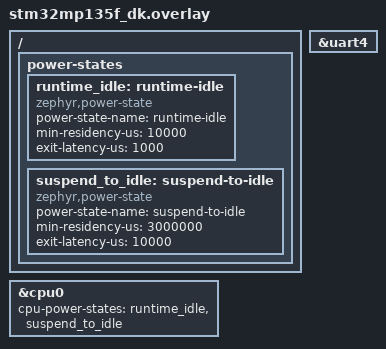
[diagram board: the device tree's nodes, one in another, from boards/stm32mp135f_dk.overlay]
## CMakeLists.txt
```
cmake_minimum_required(VERSION 3.20.0)
find_package(Zephyr REQUIRED HINTS $ENV{ZEPHYR_BASE})
project(lowpowerentry)

set(CUBE_ROOT /local/home/achraftm/zephyrproject/mp13BareMetal/stm32cubemp13-v1-2-0/STM32Cube_FW_MP13_V1.2.0)
set(CUBE_BSP_DIR ${CUBE_ROOT}/Drivers/BSP/STM32MP13xx_DISCO)
set(CUBE_HAL_DIR ${CUBE_ROOT}/Drivers/STM32MP13xx_HAL_Driver/Inc)
set(CUBE_CMSIS_DIR ${CUBE_ROOT}/Drivers/CMSIS/Device/ST/STM32MP13xx/Include)
set(CUBE_BSP_APP_INC ${CUBE_ROOT}/Projects/STM32MP135C-DK/Applications/Low_power_LPLV_Stop2/BSP_BasicTemplates_low_power/Inc)

zephyr_include_directories(
	${CMAKE_CURRENT_SOURCE_DIR}
	${CUBE_BSP_DIR}
)

target_sources(app PRIVATE
	src/main.c
	src/wakeWrap.c
	${ZEPHYR_BASE}/../modules/hal/stm32/stm32cube/stm32mp13xx/drivers/src/stm32mp13xx_hal_pwr.c
	${ZEPHYR_BASE}/../modules/hal/stm32/stm32cube/stm32mp13xx/drivers/src/stm32mp13xx_hal_pwr_ex.c
	${ZEPHYR_BASE}/../modules/hal/stm32/stm32cube/stm32mp13xx/drivers/src/stm32mp13xx_hal_gpio.c
	${ZEPHYR_BASE}/../modules/hal/stm32/stm32cube/stm32mp13xx/drivers/src/stm32mp13xx_hal_exti.c
	${ZEPHYR_BASE}/../modules/hal/stm32/stm32cube/stm32mp13xx/drivers/src/stm32mp13xx_hal_i2c.c
	${ZEPHYR_BASE}/../modules/hal/stm32/stm32cube/stm32mp13xx/drivers/src/stm32mp13xx_hal_uart.c
	${ZEPHYR_BASE}/../modules/hal/stm32/stm32cube/stm32mp13xx/drivers/src/stm32mp13xx_hal_rtc.c
	${ZEPHYR_BASE}/../modules/hal/stm32/stm32cube/stm32mp13xx/drivers/src/stm32mp13xx_hal_rtc_ex.c
	${ZEPHYR_BASE}/../modules/hal/stm32/stm32cube/stm32mp13xx/drivers/src/stm32mp13xx_hal_ddr.c
	${ZEPHYR_BASE}/../modules/hal/stm32/stm32cube/stm32mp13xx/drivers/src/stm32mp13xx_hal_bsec.c
	${CUBE_ROOT}/Drivers/CMSIS/Core_A/Source/irq_ctrl_gic.c
	${CUBE_BSP_DIR}/stm32mp13xx_disco.c
	${CUBE_BSP_DIR}/stm32mp13xx_disco_bus.c
	${CUBE_BSP_DIR}/stm32mp13xx_disco_stpmic1.c
)

target_include_directories(app PRIVATE
	${CUBE_BSP_APP_INC}
	${CUBE_ROOT}/Drivers/CMSIS/Core_A/Include
	${CUBE_HAL_DIR}
	${CUBE_CMSIS_DIR}
)

target_compile_definitions(app PRIVATE
	USE_STM32MP13XX_DK
	HAL_DDR_MODULE_ENABLED
	DDR_TYPE_DDR3_4Gb
	HAL_BSEC_MODULE_ENABLED
)
```

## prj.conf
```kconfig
CONFIG_PRINTK=y
CONFIG_CONSOLE=y
CONFIG_SERIAL=y
CONFIG_UART_CONSOLE=y
CONFIG_STDOUT_CONSOLE=y
CONFIG_PM=y
CONFIG_TICKLESS_KERNEL=y
```

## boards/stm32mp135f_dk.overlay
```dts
&uart4 {
	/delete-property/ wakeup-source;
};

/ {
	power-states {
		runtime_idle: runtime-idle {
			compatible = "zephyr,power-state";
			power-state-name = "runtime-idle";
			min-residency-us = <10000>;
			exit-latency-us = <1000>;
		};

		suspend_to_idle: suspend-to-idle {
			compatible = "zephyr,power-state";
			power-state-name = "suspend-to-idle";
			min-residency-us = <3000000>;
			exit-latency-us = <10000>;
		};
	};
};

&cpu0 {
	cpu-power-states = <&runtime_idle &suspend_to_idle>;
};
```

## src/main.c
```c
#include "main.h"
#include <zephyr/sys/printk.h>
#include <zephyr/pm/pm.h>
#include <zephyr/pm/state.h>
#include <zephyr/devicetree.h>
#include <zephyr/drivers/gpio.h>
#include "src/wakeWrap.h"

RTC_HandleTypeDef RTCHandle_BKUP;


int main(void)
{
	printk("Hello World - Landed in user application in DDR\n\r");
	uint32_t count = 0;

	HAL_RTC_Init(&RTCHandle_BKUP);
	printk("step: backup register written\n\r");
	//HAL_RTCEx_BKUPWrite(&RTCHandle_BKUP, RTC_BKP_DR0,(uint32_t) (&main));

	while (count < 6) {
		BSP_LED_Toggle(LED_BLUE);
		k_busy_wait(100000); /* 100 ms */
		BSP_LED_Toggle(LED_RED);
		count++;
	}

	BSP_LED_Off(LED_BLUE);
	BSP_LED_Off(LED_RED);

	HAL_PWR_EnableWakeUpPinIT(PWR_WAKEUP_PIN1);
	HAL_PWR_EnableWakeUpPin(PWR_WAKEUP_PIN1_LOW);
	IRQ_Enable(MPU_WAKEUP_PIN_IRQn);
	HAL_Delay(1000);

	while (1) {
		BSP_LED_Toggle(LED_BLUE);
		k_busy_wait(100000); /* 100 ms */
		BSP_LED_Toggle(LED_RED);
	}
}
```

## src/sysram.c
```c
#include <stdint.h>
#include <string.h>

#include <stm32mp13xx_hal.h>
#include <stm32mp13xx_hal_rtc.h>
#include <stm32mp13xx_hal_rtc_ex.h>

#include "sysram.h"

#define SYSRAM_START 0x2FFE0000U
#define SYSRAM_END   0x30000000U

#define DDRCTRL_BASE_ADDR  0x5A003000U
#define DDRPHYC_BASE_ADDR  0x5A004000U
#define PWR_BASE_ADDR      0x50001000U
#define TAMP_BASE_ADDR     0x5C00A000U

#define DDRCTRL_STAT_OFFSET    0x004U
#define DDRCTRL_PWRCTL_OFFSET  0x030U
#define DDRPHYC_ZQ0CR0_OFFSET  0x180U
#define PWR_CR3_OFFSET         0x00CU
#define TAMP_BKP2R_OFFSET      0x108U

#define DDRCTRL_STAT_OPERATING_MODE_NML  0x00000001U
#define DDRCTRL_STAT_OPERATING_MODE_SR   0x00000003U
#define DDRCTRL_STAT_SELFREF_TYPE_SW     0x00000020U

#ifndef DDRCTRL_STAT_OPERATING_MODE_Msk
#define DDRCTRL_STAT_OPERATING_MODE_Msk  0x00000007U
#endif

#ifndef DDRCTRL_STAT_SELFREF_TYPE_Msk
#define DDRCTRL_STAT_SELFREF_TYPE_Msk    0x00000030U
#endif

#ifndef DDRCTRL_PWRCTL_SELFREF_SW
#define DDRCTRL_PWRCTL_SELFREF_SW        0x00000020U
#endif

#ifndef DDRCTRL_PWRCTL_SELFREF_EN
#define DDRCTRL_PWRCTL_SELFREF_EN        0x00000001U
#endif

#ifndef DDRCTRL_PWRCTL_EN_DFI_DRAM_CLK_DISABLE
#define DDRCTRL_PWRCTL_EN_DFI_DRAM_CLK_DISABLE 0x00000008U
#endif

#ifndef DDRPHYC_ZQ0CR0_ZDATA_Msk
#define DDRPHYC_ZQ0CR0_ZDATA_Msk         0x000FFFFFU
#endif

#ifndef PWR_CR3_DDRSREN
#define PWR_CR3_DDRSREN                  0x00010000U
#endif

#ifndef PWR_CR3_DDRRETEN
#define PWR_CR3_DDRRETEN                 0x00020000U
#endif

/* GPIO A LED control (LD3 is active-low on pin 14). */
#define GPIOA_BASE_ADDR   0x50002000U
#define GPIO_MODER_OFFSET 0x00U
#define GPIO_OTYPER_OFFSET 0x04U
#define GPIO_PUPDR_OFFSET 0x0CU
#define GPIO_BSRR_OFFSET  0x18U
#define LED_PIN           14U
#define LED_PIN_MASK      (1U << LED_PIN)

#define STUB_WAIT_TIMEOUT      50000000U
#define BLINK_HALF_PERIOD_NOPS 200000U

#define SYSRAM_DDR_SW_SELF_REFRESH_MODE 0x0U
#define SYSRAM_DDR_AUTO_SELF_REFRESH_MODE 0x1U
#define SYSRAM_DDR_HW_SELF_REFRESH_MODE 0x2U
#define SYSRAM_DDR_INVALID_MODE 0x3U

extern uint8_t __sysram_text_start[];
extern uint8_t __sysram_text_end[];
extern uint8_t __sysram_text_load_start[];

__attribute__((section(".sysram_bss")))
static struct ddr_sr_result sysram_result;

__attribute__((section(".sysram_bss"), aligned(8)))
static uint8_t sysram_stack[1024];

static inline uint32_t mmio_read32(uint32_t addr)
{
	return *(volatile uint32_t *)addr;
}

static inline void mmio_write32(uint32_t addr, uint32_t val)
{
	*(volatile uint32_t *)addr = val;
}

static inline void mmio_set_bits32(uint32_t addr, uint32_t mask)
{
	mmio_write32(addr, mmio_read32(addr) | mask);
}

static inline void mmio_clear_bits32(uint32_t addr, uint32_t mask)
{
	mmio_write32(addr, mmio_read32(addr) & ~mask);
}

extern RTC_HandleTypeDef RTCHandle_BKUP;

static HAL_StatusTypeDef ddr_sr_mode_ssr(void)
{
	const uint32_t pwrctl_addr = DDRCTRL_BASE_ADDR + DDRCTRL_PWRCTL_OFFSET;

	/* SW mode in HAL: no auto self-refresh and no clock-disable LP mode. */
	mmio_clear_bits32(pwrctl_addr,
			      DDRCTRL_PWRCTL_EN_DFI_DRAM_CLK_DISABLE |
			      DDRCTRL_PWRCTL_SELFREF_EN);

	return HAL_OK;
}

static HAL_StatusTypeDef ddr_sr_mode_asr(void)
{
	const uint32_t pwrctl_addr = DDRCTRL_BASE_ADDR + DDRCTRL_PWRCTL_OFFSET;

	/* ASR mode in HAL: auto self-refresh + clock-disable LP mode. */
	mmio_set_bits32(pwrctl_addr,
		    DDRCTRL_PWRCTL_EN_DFI_DRAM_CLK_DISABLE |
		    DDRCTRL_PWRCTL_SELFREF_EN);

	return HAL_OK;
}

static HAL_StatusTypeDef ddr_sr_mode_hsr(void)
{
	const uint32_t pwrctl_addr = DDRCTRL_BASE_ADDR + DDRCTRL_PWRCTL_OFFSET;

	/* HSR mode in HAL: clock-disable LP mode enabled, auto self-refresh disabled. */
	mmio_set_bits32(pwrctl_addr, DDRCTRL_PWRCTL_EN_DFI_DRAM_CLK_DISABLE);
	mmio_clear_bits32(pwrctl_addr, DDRCTRL_PWRCTL_SELFREF_EN);

	return HAL_OK;
}

static uint32_t ddr_sr_read_mode(void)
{
	const uint32_t pwrctl_addr = DDRCTRL_BASE_ADDR + DDRCTRL_PWRCTL_OFFSET;
	uint32_t pwrctl = mmio_read32(pwrctl_addr);

	switch (pwrctl & (DDRCTRL_PWRCTL_EN_DFI_DRAM_CLK_DISABLE |
				 DDRCTRL_PWRCTL_SELFREF_EN)) {
	case 0U:
		return SYSRAM_DDR_SW_SELF_REFRESH_MODE;
	case DDRCTRL_PWRCTL_EN_DFI_DRAM_CLK_DISABLE:
		return SYSRAM_DDR_HW_SELF_REFRESH_MODE;
	case DDRCTRL_PWRCTL_EN_DFI_DRAM_CLK_DISABLE | DDRCTRL_PWRCTL_SELFREF_EN:
		return SYSRAM_DDR_AUTO_SELF_REFRESH_MODE;
	default:
		return SYSRAM_DDR_INVALID_MODE;
	}
}

/* HAL-like helper: enter software self-refresh and wait for status transition. */
static HAL_StatusTypeDef ddr_sw_self_refresh_in(void)
{
	uint32_t stat;
	uint32_t timeout;
	const uint32_t pwrctl_addr = DDRCTRL_BASE_ADDR + DDRCTRL_PWRCTL_OFFSET;
	const uint32_t stat_addr = DDRCTRL_BASE_ADDR + DDRCTRL_STAT_OFFSET;

	mmio_set_bits32(pwrctl_addr, DDRCTRL_PWRCTL_SELFREF_SW);

	timeout = STUB_WAIT_TIMEOUT;
	do {
		stat = mmio_read32(stat_addr);
		if (((stat & DDRCTRL_STAT_OPERATING_MODE_Msk) == DDRCTRL_STAT_OPERATING_MODE_SR) &&
		    ((stat & DDRCTRL_STAT_SELFREF_TYPE_Msk) == DDRCTRL_STAT_SELFREF_TYPE_SW)) {
			return HAL_OK;
		}
	} while (--timeout != 0U);

	return HAL_TIMEOUT;
}

/* HAL-like helper: clear software self-refresh request and wait for normal mode. */
static HAL_StatusTypeDef ddr_sw_self_refresh_out(void)
{
	uint32_t stat;
	uint32_t timeout;
	const uint32_t pwrctl_addr = DDRCTRL_BASE_ADDR + DDRCTRL_PWRCTL_OFFSET;
	const uint32_t stat_addr = DDRCTRL_BASE_ADDR + DDRCTRL_STAT_OFFSET;

	mmio_clear_bits32(pwrctl_addr, DDRCTRL_PWRCTL_SELFREF_SW);

	timeout = STUB_WAIT_TIMEOUT;
	do {
		stat = mmio_read32(stat_addr);
		if ((stat & DDRCTRL_STAT_OPERATING_MODE_Msk) == DDRCTRL_STAT_OPERATING_MODE_NML) {
			return HAL_OK;
		}
	} while (--timeout != 0U);

	return HAL_TIMEOUT;
}

/* Copied/adapted from HAL_DDR_SR_Entry. */
static HAL_StatusTypeDef sysram_ddr_sr_entry(uint32_t *zq0cr0_zdata)
{
	if (zq0cr0_zdata != NULL) {
		*zq0cr0_zdata = mmio_read32(DDRPHYC_BASE_ADDR + DDRPHYC_ZQ0CR0_OFFSET) & DDRPHYC_ZQ0CR0_ZDATA_Msk;
	}

	if (ddr_sw_self_refresh_in() != HAL_OK) {
		return HAL_ERROR;
	}

	mmio_set_bits32(PWR_BASE_ADDR + PWR_CR3_OFFSET, PWR_CR3_DDRSREN);

	return HAL_OK;
}

/* Copied/adapted from HAL_DDR_SR_Exit. */
static HAL_StatusTypeDef sysram_ddr_sr_exit(void)
{
	HAL_StatusTypeDef ret;

	ret = ddr_sw_self_refresh_out();
	if (ret != HAL_OK) {
		return ret;
	}

	mmio_clear_bits32(PWR_BASE_ADDR + PWR_CR3_OFFSET, PWR_CR3_DDRRETEN);

	return HAL_OK;
}

/* Copied/adapted from HAL_DDR_SR_SetMode. */
static HAL_StatusTypeDef sysram_ddr_sr_setmode(uint32_t mode)
{
	HAL_StatusTypeDef ret;

	switch (mode) {
	case SYSRAM_DDR_SW_SELF_REFRESH_MODE:
		ret = ddr_sr_mode_ssr();
		break;
	case SYSRAM_DDR_AUTO_SELF_REFRESH_MODE:
		ret = ddr_sr_mode_asr();
		break;
	case SYSRAM_DDR_HW_SELF_REFRESH_MODE:
		ret = ddr_sr_mode_hsr();
		break;
	default:
		ret = HAL_ERROR;
		break;
	}

	return ret;
}

/* Copied/adapted from HAL_DDR_SR_ReadMode. */
static uint32_t sysram_ddr_sr_readmode(void)
{
	return ddr_sr_read_mode();
}

/* RTC handoff helper: fetch FSBL entry from BKP_DR2 and jump to it. */
__attribute__((noreturn))
static void sysram_jump_to_fsbl_from_bkp_dr2(void)
{
	uintptr_t jump_target;
	const uint32_t bkp2r_addr = TAMP_BASE_ADDR + TAMP_BKP2R_OFFSET;

	/* Direct read avoids HAL RTC call dependencies during SYSRAM handoff. */
	jump_target = (uintptr_t)mmio_read32(bkp2r_addr);
	__asm__ volatile("bx %0" : : "r"(jump_target) : "memory");
	__builtin_unreachable();
}

static void led_init(void)
{
	uint32_t moder;
	uint32_t otyper;
	uint32_t pupdr;

	moder = mmio_read32(GPIOA_BASE_ADDR + GPIO_MODER_OFFSET);
	moder &= ~(0x3U << (LED_PIN * 2U));
	moder |= (0x1U << (LED_PIN * 2U));
	mmio_write32(GPIOA_BASE_ADDR + GPIO_MODER_OFFSET, moder);

	otyper = mmio_read32(GPIOA_BASE_ADDR + GPIO_OTYPER_OFFSET);
	otyper &= ~LED_PIN_MASK;
	mmio_write32(GPIOA_BASE_ADDR + GPIO_OTYPER_OFFSET, otyper);

	pupdr = mmio_read32(GPIOA_BASE_ADDR + GPIO_PUPDR_OFFSET);
	pupdr &= ~(0x3U << (LED_PIN * 2U));
	mmio_write32(GPIOA_BASE_ADDR + GPIO_PUPDR_OFFSET, pupdr);

	/* Active-low LED off. */
	mmio_write32(GPIOA_BASE_ADDR + GPIO_BSRR_OFFSET, LED_PIN_MASK);
}

static void copy_sysram_sections(void)
{
	size_t size;

	size = (size_t)(__sysram_text_end - __sysram_text_start);
	memcpy(__sysram_text_start, __sysram_text_load_start, size);
}

__attribute__((section(".sysram_text"), noinline, used))
static void ddr_sr_stub(struct ddr_sr_result *result)
{
	uint32_t stat;
	HAL_StatusTypeDef ret;
	const uint32_t stat_addr = DDRCTRL_BASE_ADDR + DDRCTRL_STAT_OFFSET;
	const uint32_t gpioa_bsrr_addr = GPIOA_BASE_ADDR + GPIO_BSRR_OFFSET;

	result->started = 1U;
	result->phase = 1U;

	if (sysram_ddr_sr_setmode(SYSRAM_DDR_SW_SELF_REFRESH_MODE) != HAL_OK) {
		result->phase = 0xE0U;
		return;
	}

	if (sysram_ddr_sr_readmode() != SYSRAM_DDR_SW_SELF_REFRESH_MODE) {
		result->phase = 0xE4U;
		return;
	}

	ret = sysram_ddr_sr_entry(&result->zdata);
	result->phase = 2U;
	stat = mmio_read32(stat_addr);
	result->entry_stat = stat;
	result->entry_ok = (ret == HAL_OK) ? 1U : 0U;
	if (!result->entry_ok) {
		result->phase = 0xE1U;
		return;
	}

	result->phase = 3U;

	for (uint32_t blink_count = 0U; blink_count < 10U; blink_count++) {
		mmio_write32(gpioa_bsrr_addr, LED_PIN_MASK << 16);
		for (volatile uint32_t delay = 0U; delay < BLINK_HALF_PERIOD_NOPS; delay++) {
			__asm__ volatile("nop");
		}

		mmio_write32(gpioa_bsrr_addr, LED_PIN_MASK);
		for (volatile uint32_t delay = 0U; delay < BLINK_HALF_PERIOD_NOPS; delay++) {
			__asm__ volatile("nop");
		}
	}

	sysram_jump_to_fsbl_from_bkp_dr2();

	ret = sysram_ddr_sr_exit();
	result->phase = 4U;
	stat = mmio_read32(stat_addr);
	result->exit_stat = stat;
	result->exit_ok = (ret == HAL_OK) ? 1U : 0U;
	if (!result->exit_ok) {
		result->phase = 0xE2U;
		result->finished = 1U;
		return;
	}

	result->phase = 5U;
	result->finished = 1U;
}

void sysram_init(void)
{
	led_init();
	copy_sysram_sections();
	__asm__ volatile("dsb" ::: "memory");
	__asm__ volatile("isb" ::: "memory");
	memset(&sysram_result, 0, sizeof(sysram_result));
}

__attribute__((section(".sysram_text"), noinline, used))
void sysram_run(void)
{
	register uintptr_t old_sp;
	uintptr_t new_sp = (uintptr_t)(sysram_stack + sizeof(sysram_stack));

	__asm__ volatile("mov %0, sp" : "=r"(old_sp));
	__asm__ volatile("mov sp, %0" : : "r"(new_sp) : "memory");

	ddr_sr_stub(&sysram_result);

	__asm__ volatile("mov sp, %0" : : "r"(old_sp) : "memory");
}

const struct ddr_sr_result *sysram_get_result(void)
{
	return &sysram_result;
}

uintptr_t sysram_get_stub_addr(void)
{
	return (uintptr_t)ddr_sr_stub & ~(uintptr_t)0x1U;
}

uintptr_t sysram_get_result_addr(void)
{
	return (uintptr_t)&sysram_result;
}

uintptr_t sysram_get_stack_addr(void)
{
	return (uintptr_t)sysram_stack;
}

size_t sysram_get_text_size(void)
{
	return (size_t)(__sysram_text_end - __sysram_text_start);
}
```

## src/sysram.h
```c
#pragma once

#include <stddef.h>
#include <stdint.h>

struct ddr_sr_result {
	uint32_t started;
	uint32_t phase;
	uint32_t finished;
	uint32_t zdata;
	uint32_t entry_stat;
	uint32_t exit_stat;
	uint32_t entry_ok;
	uint32_t exit_ok;
};

void sysram_init(void);
void sysram_run(void);

const struct ddr_sr_result *sysram_get_result(void);
uintptr_t sysram_get_stub_addr(void);
uintptr_t sysram_get_result_addr(void);
uintptr_t sysram_get_stack_addr(void);
size_t sysram_get_text_size(void);
```

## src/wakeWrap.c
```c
#include "main.h"
#include "wakeWrap.h"
#include <zephyr/arch/arm/mmu/arm_mem.h>
#include <zephyr/kernel.h>
#include <zephyr/kernel/mm.h>
#include <zephyr/sys/printk.h>
#include <stm32mp13xx_hal_rtc.h>
#include <stm32mp13xx_hal_rtc_ex.h>

#define FSBL_SYSRAM_BASE 0x2FFE0000U
#define FSBL_SYSRAM_SIZE 0x00020000U

extern RTC_HandleTypeDef RTCHandle_BKUP;
void arch_mem_map(void *virt, uintptr_t phys, size_t size, uint32_t flags);

void wokeup(void)
{
	uintptr_t fsbl_entry = HAL_RTCEx_BKUPRead(&RTCHandle_BKUP, RTC_BKP_DR2);

	printk("PM: BKP_DR2 jump target = 0x%08x\n", (uint32_t)fsbl_entry);
	printk("step: fsbl entrypoint loaded\n\r");

	arch_mem_map((void *)FSBL_SYSRAM_BASE, FSBL_SYSRAM_BASE, FSBL_SYSRAM_SIZE,
		     K_MEM_ARM_NORMAL_NC | K_MEM_PERM_RW | K_MEM_PERM_EXEC);
	printk("step: fsbl sysram mapped\n\r");

	printk("step: jumping to fsbl entry 0x%08x\n\r", (uint32_t)fsbl_entry);

	__asm__ volatile("bx %0" : : "r"(fsbl_entry) : "memory");
	__builtin_unreachable();
}
```

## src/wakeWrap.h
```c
#ifndef WAKE_WRAP_H_
#define WAKE_WRAP_H_

void wokeup(void);

#endif /* WAKE_WRAP_H_ */
```
